# CH32V20xxx register map
Vendor: WCH Ltd.; File version: 1.0
Registers are 32-bit, read-write, reset 0x0 unless marked. A register's access mark holds for its fields unless they carry their own. Offsets are from the block's base; [hi:lo] are bit positions.

## ETHERNET_DMA — Ethernet: DMA controller operation
Base 0x40029000
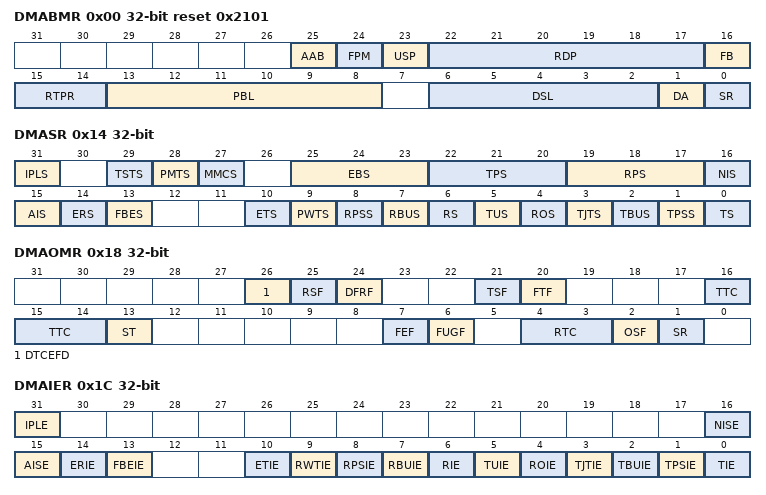
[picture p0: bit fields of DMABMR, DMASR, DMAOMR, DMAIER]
0x00 DMABMR reset 0x2101 — Ethernet DMA bus mode register
  [25] AAB — Address-aligned beats
  [24] FPM — 4xPBL mode
  [23] USP — Use separate PBL
  [22:17] RDP — Rx DMA PBL
  [16] FB — Fixed burst
  [15:14] RTPR — Rx Tx priority ratio
  [13:8] PBL — Programmable burst length
  [6:2] DSL — Descriptor skip length
  [1] DA — DMA Arbitration
  [0] SR — Software reset
0x04 DMATPDR — Ethernet DMA transmit poll demand register
  [31:0] TPD — Transmit poll demand
0x08 DMARPDR — EHERNET DMA receive poll demand register
  [31:0] RPD — Receive poll demand
0x0C DMARDLAR — Ethernet DMA receive descriptor list address register
  [31:0] SRL — Start of receive list
0x10 DMATDLAR — Ethernet DMA transmit descriptor list address register
  [31:0] STL — Start of transmit list
0x14 DMASR access per field — Ethernet DMA status register
  [31] IPLS ro — 10MPHY Physical layer variation
  [29] TSTS ro — Time stamp trigger status
  [28] PMTS ro — PMT status
  [27] MMCS ro — MMC status
  [25:23] EBS ro — Error bits status
  [22:20] TPS ro — Transmit process state
  [19:17] RPS ro — Receive process state
  [16] NIS read/clear — Normal interrupt summary
  [15] AIS read/clear — Abnormal interrupt summary
  [14] ERS read/clear — Early receive status
  [13] FBES read/clear — Fatal bus error status
  [10] ETS read/clear — Early transmit status
  [9] PWTS read/clear — Receive watchdog timeout status
  [8] RPSS read/clear — Receive process stopped status
  [7] RBUS read/clear — Receive buffer unavailable status
  [6] RS read/clear — Receive status
  [5] TUS read/clear — Transmit underflow status
  [4] ROS read/clear — Receive overflow status
  [3] TJTS read/clear — Transmit jabber timeout status
  [2] TBUS read/clear — Transmit buffer unavailable status
  [1] TPSS read/clear — Transmit process stopped status
  [0] TS read/clear — Transmit status
0x18 DMAOMR — Ethernet DMA operation mode register
  [26] DTCEFD, [25] RSF, [24] DFRF, [21] TSF, [20] FTF, [16:14] TTC, [13] ST, [7] FEF, [6] FUGF, [4:3] RTC, [2] OSF, [1] SR
0x1C DMAIER — Ethernet DMA interrupt enable register
  [31] IPLE — 10M Physical layer connection
  [16] NISE — Normal interrupt summary enable
  [15] AISE — Abnormal interrupt summary enable
  [14] ERIE — Early receive interrupt enable
  [13] FBEIE — Fatal bus error interrupt enable
  [10] ETIE — Early transmit interrupt enable
  [9] RWTIE — receive watchdog timeout interrupt enable
  [8] RPSIE — Receive process stopped interrupt enable
  [7] RBUIE — Receive buffer unavailable interrupt enable
  [6] RIE — Receive interrupt enable
  [5] TUIE — Underflow interrupt enable
  [4] ROIE — Overflow interrupt enable
  [3] TJTIE — Transmit jabber timeout interrupt enable
  [2] TBUIE — Transmit buffer unavailable interrupt enable
  [1] TPSIE — Transmit process stopped interrupt enable
  [0] TIE — Transmit interrupt enable
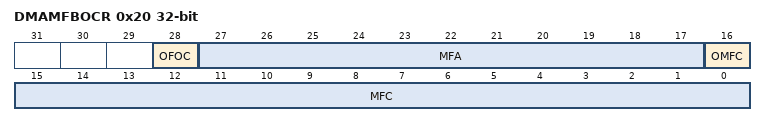
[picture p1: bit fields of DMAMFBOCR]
0x20 DMAMFBOCR ro — Ethernet DMA missed frame and buffer overflow counter register
  [28] OFOC — Overflow bit for FIFO overflow counter
  [27:17] MFA — Missed frames by the application
  [16] OMFC — Overflow bit for missed frame counter
  [15:0] MFC — Missed frames by the controller
0x48 DMACHTDR ro — Ethernet DMA current host transmit descriptor register
  [31:0] HTDAP — Host transmit descriptor address pointer
0x4C DMACHRDR ro — Ethernet DMA current host receive descriptor register
  [31:0] HRDAP — Host receive descriptor address pointer
0x50 DMACHTBAR ro — Ethernet DMA current host transmit buffer address register
  [31:0] HTBAP — Host transmit buffer address pointer
0x54 DMACHRBAR ro — Ethernet DMA current host receive buffer address register
  [31:0] HRBAP — Host receive buffer address pointer
